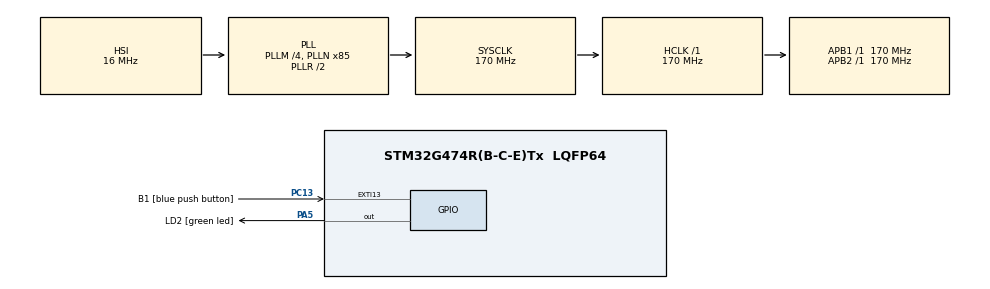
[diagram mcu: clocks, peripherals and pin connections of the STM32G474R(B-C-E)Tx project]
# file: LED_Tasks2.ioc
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Mcu.Family=STM32G4
Mcu.Name=STM32G474R(B-C-E)Tx
Mcu.Package=LQFP64
NVIC.EXTI15_10_IRQn=true\:0\:0\:false\:false\:true\:true\:true\:true
NVIC.PriorityGroup=NVIC_PRIORITYGROUP_4
NVIC.TIM6_DAC_IRQn=true\:15\:0\:false\:false\:true\:false\:true\:true
NVIC.TimeBase=TIM6_DAC_IRQn
NVIC.TimeBaseIP=TIM6
PA13.GPIO_Label=T_SWDIO
PA13.Signal=SYS_JTMS-SWDIO
PA14.GPIO_Label=T_SWCLK
PA14.Signal=SYS_JTCK-SWCLK
PA2.GPIO_Label=LPUART1_TX [STLINKV3E_VCP_RX]
PA2.Signal=LPUART1_TX
PA3.GPIO_Label=LPUART1_RX [STLINKV3E_VCP_TX]
PA3.Signal=LPUART1_RX
PA5.GPIO_Label=LD2 [green led]
PA5.Signal=GPIO_Output
PB3.GPIO_Label=T_SWO
PB3.Signal=SYS_JTDO-SWO
PC13.GPIO_Label=B1 [blue push button]
PC13.Signal=GPXTI13
PC14-OSC32_IN.Signal=RCC_OSC32_IN
PC15-OSC32_OUT.Signal=RCC_OSC32_OUT
PF0-OSC_IN.Signal=RCC_OSC_IN
PF1-OSC_OUT.Signal=RCC_OSC_OUT
ProjectManager.HeapSize=0x200
ProjectManager.StackSize=0x400
ProjectManager.TargetToolchain=STM32CubeIDE
RCC.ADC12Freq_Value=170000000
RCC.ADC345Freq_Value=170000000
RCC.AHBFreq_Value=170000000
RCC.APB1Freq_Value=170000000
RCC.APB1TimFreq_Value=170000000
RCC.APB2Freq_Value=170000000
RCC.APB2TimFreq_Value=170000000
RCC.CortexFreq_Value=170000000
RCC.EXTERNAL_CLOCK_VALUE=12288000
RCC.HCLKFreq_Value=170000000
RCC.HSE_VALUE=24000000
RCC.HSI48_VALUE=48000000
RCC.HSI_VALUE=16000000
RCC.LSE_VALUE=32768
RCC.PLLM=RCC_PLLM_DIV4
RCC.PLLN=85
RCC.RTCClockSelection=RCC_RTCCLKSOURCE_LSE
RCC.SYSCLKFreq_VALUE=170000000
RCC.SYSCLKSource=RCC_SYSCLKSOURCE_PLLCLK
RCC.USBFreq_Value=170000000
RCC.VCOOutputFreq_Value=340000000
VP_SYS_VS_DBSignals.Mode=DisableDeadBatterySignals
VP_SYS_VS_tim6.Mode=TIM6
board=NUCLEO-G474RE

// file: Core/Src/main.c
/* USER CODE BEGIN Header */
/**
  ******************************************************************************
  * @file           : main.c
  * @brief          : Main program body
  ******************************************************************************
  * @attention
  *
  * Copyright (c) 2023 STMicroelectronics.
  * All rights reserved.
  *
  * This software is licensed under terms that can be found in the LICENSE file
  * in the root directory of this software component.
  * If no LICENSE file comes with this software, it is provided AS-IS.
  *
  ******************************************************************************
  */
/* USER CODE END Header */
#include "main.h"

/* USER CODE BEGIN Includes */
#include <stdio.h>
#include "FreeRTOS.h"
#include "task.h"
/* USER CODE END Includes */

/* USER CODE BEGIN PV */
#define DWT_CTRL	(*(volatile uint32_t*)0xE0001000)
/* USER CODE END PV */

void SystemClock_Config(void);
static void MX_GPIO_Init(void);
/* USER CODE BEGIN PFP */
static void led_green_handler(void* parameters);
static void led_red_handler(void* parameters);
static void led_orange_handler(void* parameters);
/* USER CODE END PFP */

int main(void)
{
  /* USER CODE BEGIN 1 */

  TaskHandle_t task1_handle;
  TaskHandle_t task2_handle;
  TaskHandle_t task3_handle;

  BaseType_t status;

  /* USER CODE END 1 */

  /* MCU Configuration--------------------------------------------------------*/

  /* Reset of all peripherals, Initializes the Flash interface and the Systick. */
  HAL_Init();

  /* Configure the system clock */
  SystemClock_Config();

  /* Initialize all configured peripherals */
  MX_GPIO_Init();
  /* USER CODE BEGIN 2 */

  // Enable the cycle counter
  DWT_CTRL |= ( 1 << 0 );

  SEGGER_SYSVIEW_Conf();
  SEGGER_SYSVIEW_Start();

  status = xTaskCreate(led_green_handler, "LED_green_task", 200, NULL, 2, &task1_handle);

  configASSERT(status == pdPASS);

  status = xTaskCreate(led_red_handler, "LED_red_task", 200, NULL, 2, &task2_handle);

  configASSERT(status == pdPASS);

  status = xTaskCreate(led_orange_handler, "LED_orange_task", 200, NULL, 2, &task3_handle);

  configASSERT(status == pdPASS);

  // start the freeRTOS scheduler
  vTaskStartScheduler();

  /* USER CODE END 2 */

  /* Infinite loop */
  while (1)
  {

  }
}

void SystemClock_Config(void)
{
  RCC_OscInitTypeDef RCC_OscInitStruct = {0};
  RCC_ClkInitTypeDef RCC_ClkInitStruct = {0};

  /** Configure the main internal regulator output voltage
  */
  HAL_PWREx_ControlVoltageScaling(PWR_REGULATOR_VOLTAGE_SCALE1_BOOST);

  /** Initializes the RCC Oscillators according to the specified parameters
  * in the RCC_OscInitTypeDef structure.
  */
  RCC_OscInitStruct.OscillatorType = RCC_OSCILLATORTYPE_HSI;
  RCC_OscInitStruct.HSIState = RCC_HSI_ON;
  RCC_OscInitStruct.HSICalibrationValue = RCC_HSICALIBRATION_DEFAULT;
  RCC_OscInitStruct.PLL.PLLState = RCC_PLL_ON;
  RCC_OscInitStruct.PLL.PLLSource = RCC_PLLSOURCE_HSI;
  RCC_OscInitStruct.PLL.PLLM = RCC_PLLM_DIV4;
  RCC_OscInitStruct.PLL.PLLN = 85;
  RCC_OscInitStruct.PLL.PLLP = RCC_PLLP_DIV2;
  RCC_OscInitStruct.PLL.PLLQ = RCC_PLLQ_DIV2;
  RCC_OscInitStruct.PLL.PLLR = RCC_PLLR_DIV2;
  if (HAL_RCC_OscConfig(&RCC_OscInitStruct) != HAL_OK)
  {
    Error_Handler();
  }

  /** Initializes the CPU, AHB and APB buses clocks
  */
  RCC_ClkInitStruct.ClockType = RCC_CLOCKTYPE_HCLK|RCC_CLOCKTYPE_SYSCLK
                              |RCC_CLOCKTYPE_PCLK1|RCC_CLOCKTYPE_PCLK2;
  RCC_ClkInitStruct.SYSCLKSource = RCC_SYSCLKSOURCE_PLLCLK;
  RCC_ClkInitStruct.AHBCLKDivider = RCC_SYSCLK_DIV1;
  RCC_ClkInitStruct.APB1CLKDivider = RCC_HCLK_DIV1;
  RCC_ClkInitStruct.APB2CLKDivider = RCC_HCLK_DIV1;

  if (HAL_RCC_ClockConfig(&RCC_ClkInitStruct, FLASH_LATENCY_4) != HAL_OK)
  {
    Error_Handler();
  }
}

static void MX_GPIO_Init(void)
{
  GPIO_InitTypeDef GPIO_InitStruct = {0};

  /* GPIO Ports Clock Enable */
  __HAL_RCC_GPIOC_CLK_ENABLE();
  __HAL_RCC_GPIOF_CLK_ENABLE();
  __HAL_RCC_GPIOA_CLK_ENABLE();
  __HAL_RCC_GPIOB_CLK_ENABLE();

  /*Configure GPIO pin Output Level */
  HAL_GPIO_WritePin(LD2_GPIO_Port, LD2_Pin, GPIO_PIN_RESET);

  /*Configure GPIO pin : B1_Pin */
  GPIO_InitStruct.Pin = B1_Pin;
  GPIO_InitStruct.Mode = GPIO_MODE_IT_RISING;
  GPIO_InitStruct.Pull = GPIO_NOPULL;
  HAL_GPIO_Init(B1_GPIO_Port, &GPIO_InitStruct);

  /*Configure GPIO pins : LPUART1_TX_Pin LPUART1_RX_Pin */
  GPIO_InitStruct.Pin = LPUART1_TX_Pin|LPUART1_RX_Pin;
  GPIO_InitStruct.Mode = GPIO_MODE_AF_PP;
  GPIO_InitStruct.Pull = GPIO_NOPULL;
  GPIO_InitStruct.Speed = GPIO_SPEED_FREQ_LOW;
  GPIO_InitStruct.Alternate = GPIO_AF12_LPUART1;
  HAL_GPIO_Init(GPIOA, &GPIO_InitStruct);

  /*Configure GPIO pin : LD2_Pin */
  GPIO_InitStruct.Pin = LD2_Pin;
  GPIO_InitStruct.Mode = GPIO_MODE_OUTPUT_PP;
  GPIO_InitStruct.Pull = GPIO_NOPULL;
  GPIO_InitStruct.Speed = GPIO_SPEED_FREQ_LOW;
  HAL_GPIO_Init(LD2_GPIO_Port, &GPIO_InitStruct);

  /* EXTI interrupt init*/
  HAL_NVIC_SetPriority(EXTI15_10_IRQn, 0, 0);
  HAL_NVIC_EnableIRQ(EXTI15_10_IRQn);

}

/* USER CODE BEGIN 4 */
static void led_green_handler(void* parameters)
{
	TickType_t last_wakeup_time;

	last_wakeup_time = xTaskGetTickCount();

	while(1)
	{
		SEGGER_SYSVIEW_PrintfTarget("Toggling green LED");
		//HAL_GPIO_TogglePin(GPIOA, GPIO_PIN_5);
		vTaskDelay(pdMS_TO_TICKS(2));
		//vTaskDelayUntil(&last_wakeup_time, pdMS_TO_TICKS(2));
	}
}

static void led_red_handler(void* parameters)
{
	TickType_t last_wakeup_time;

	last_wakeup_time = xTaskGetTickCount();

	while(1)
	{
		SEGGER_SYSVIEW_PrintfTarget("Toggling red LED");
		vTaskDelay(pdMS_TO_TICKS(2));
		//vTaskDelayUntil(&last_wakeup_time, pdMS_TO_TICKS(2));
	}
}

static void led_orange_handler(void* parameters)
{
	TickType_t last_wakeup_time;

	last_wakeup_time = xTaskGetTickCount();

	while(1)
	{
		SEGGER_SYSVIEW_PrintfTarget("Toggling orange LED");
		vTaskDelay(pdMS_TO_TICKS(2));
		//vTaskDelayUntil(&last_wakeup_time, pdMS_TO_TICKS(2));
	}
}
/* USER CODE END 4 */

void HAL_TIM_PeriodElapsedCallback(TIM_HandleTypeDef *htim)
{
  if (htim->Instance == TIM6) {
    HAL_IncTick();
  }
}

void Error_Handler(void)
{
  __disable_irq();
  while (1)
  {
  }
}
